# FSS0_FSS_GENREGS_0FC00000h register map
Vendor: Texas Instruments
Peripheral module from a debugger description file (folder AM275x).
Registers are 32-bit, read-only, reset 0x68502200 unless marked. A register's access mark holds for its fields unless they carry their own. Offsets are as the file gives them; lines under a group give offsets from that group; [hi:lo] are bit positions; {n}, {i} and the like mark numbered series; 'fields as' and 'values as' point back to an identical list; <NAME> marks a mode.

## fss_genregs
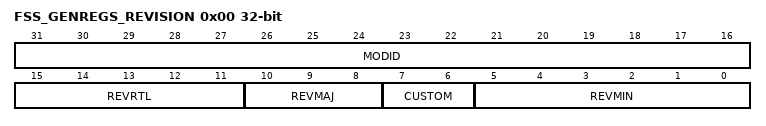
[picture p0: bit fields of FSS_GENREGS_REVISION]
0x00 FSS_GENREGS_REVISION — IP Revision Identifier (X.Y.R) Used by software to track features, bugs, and compatibility
  [31:16] MODID — Module ID field Reset Source: vbus_mod_g_rst_n
  [15:11] REVRTL — RTL revision. Will vary depending on release. Reset Source: vbus_mod_g_rst_n
  [10:8] REVMAJ — Major revision Reset Source: vbus_mod_g_rst_n
  [7:6] CUSTOM — Custom Reset Source: vbus_mod_g_rst_n
  [5:0] REVMIN — Minor revision Reset Source: vbus_mod_g_rst_n
